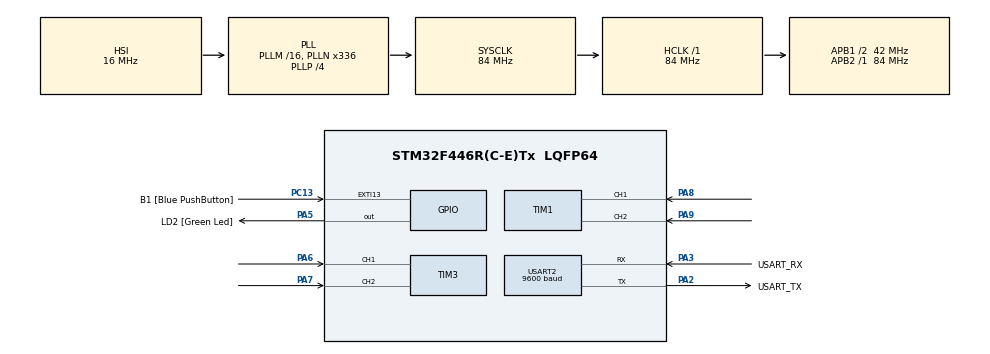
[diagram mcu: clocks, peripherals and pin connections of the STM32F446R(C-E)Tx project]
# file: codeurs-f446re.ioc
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Mcu.Family=STM32F4
PH0-OSC_IN.Signal=RCC_OSC_IN
RCC.CortexFreq_Value=84000000
PA14.GPIO_Label=TCK
TIM3.EncoderMode=TIM_ENCODERMODE_TI12
TIM1.EncoderMode=TIM_ENCODERMODE_TI12
PC13.GPIO_Label=B1 [Blue PushButton]
RCC.SYSCLKSource=RCC_SYSCLKSOURCE_PLLCLK
ProjectManager.StackSize=0x400
RCC.HCLKFreq_Value=84000000
RCC.APB2TimFreq_Value=84000000
RCC.AHBFreq_Value=84000000
PH0-OSC_IN.Mode=HSE-External-Oscillator
RCC.HSE_VALUE=8000000
PC14-OSC32_IN.Mode=LSE-External-Oscillator
PA14.Mode=Serial_Wire
PA8.Signal=S_TIM1_CH1
SH.S_TIM3_CH1.0=TIM3_CH1,Encoder_Interface
RCC.FLatency-AdvancedSettings=FLASH_LATENCY_2
PH1-OSC_OUT.Mode=HSE-External-Oscillator
Mcu.Package=LQFP64
PA6.Signal=S_TIM3_CH1
USART2.VirtualMode=VM_ASYNC
PA2.GPIO_Label=USART_TX
RCC.APB1TimFreq_Value=84000000
PA3.Signal=USART2_RX
PB3.GPIO_Label=SWO
PC15-OSC32_OUT.Mode=LSE-External-Oscillator
TIM3.CounterMode=TIM_COUNTERMODE_UP
TIM1.CounterMode=TIM_COUNTERMODE_UP
PC13.Signal=GPXTI13
RCC.APB1CLKDivider=RCC_HCLK_DIV2
PC14-OSC32_IN.Signal=RCC_OSC32_IN
USART2.BaudRate=9600
PA3.Mode=Asynchronous
PA13.Signal=SYS_JTMS-SWDIO
SH.S_TIM1_CH1.0=TIM1_CH1,Encoder_Interface
ProjectManager.TargetToolchain=STM32CubeIDE
TIM3.IC2Filter=10
PA9.Signal=S_TIM1_CH2
RCC.USBFreq_Value=168000000
PC15-OSC32_OUT.Signal=RCC_OSC32_OUT
PA5.Signal=GPIO_Output
SH.S_TIM3_CH2.0=TIM3_CH2,Encoder_Interface
TIM3.IC1Filter=10
board=NUCLEO-F446RE
RCC.VCOOutputFreq_Value=336000000
RCC.APB2Freq_Value=84000000
SH.S_TIM1_CH2.0=TIM1_CH2,Encoder_Interface
TIM1.IC2Filter=10
PH1-OSC_OUT.Signal=RCC_OSC_OUT
PA13.Mode=Serial_Wire
Mcu.Name=STM32F446R(C-E)Tx
PA13.GPIO_Label=TMS
PA2.Signal=USART2_TX
RCC.48MHZClocksFreq_Value=84000000
PB3.Signal=SYS_JTDO-SWO
RCC.SYSCLKFreq_VALUE=84000000
PA5.GPIO_Label=LD2 [Green Led]
TIM1.IC1Filter=10
PC13.GPIO_ModeDefaultEXTI=GPIO_MODE_IT_FALLING
PA14.Signal=SYS_JTCK-SWCLK
ProjectManager.HeapSize=0x200
RCC.HSI_VALUE=16000000
RCC.PLLP=RCC_PLLP_DIV4
NVIC.PriorityGroup=NVIC_PRIORITYGROUP_0
RCC.PLLN=336
PA2.Mode=Asynchronous
RCC.APB1Freq_Value=42000000
PA3.GPIO_Label=USART_RX
PA7.Signal=S_TIM3_CH2

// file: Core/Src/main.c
/* USER CODE BEGIN Header */
/**
  ******************************************************************************
  * @file           : main.c
  * @brief          : Main program body
  ******************************************************************************
  * @attention
  *
  * <h2><center>&copy; Copyright (c) 2021 STMicroelectronics.
  * All rights reserved.</center></h2>
  *
  * This software component is licensed by ST under BSD 3-Clause license,
  * the "License"; You may not use this file except in compliance with the
  * License. You may obtain a copy of the License at:
  *                        opensource.org/licenses/BSD-3-Clause
  *
  ******************************************************************************
  */
/* USER CODE END Header */
#include "main.h"
#include "tim.h"
#include "usart.h"
#include "gpio.h"

/* USER CODE BEGIN Includes */
#include <stdio.h>
#include "retarget.h"
/* USER CODE END Includes */

void SystemClock_Config(void);

int main(void)
{

  /* MCU Configuration--------------------------------------------------------*/

  /* Reset of all peripherals, Initializes the Flash interface and the Systick. */
  HAL_Init();

  /* Configure the system clock */
  SystemClock_Config();

  /* Initialize all configured peripherals */
  MX_GPIO_Init();
  MX_USART2_UART_Init();
  MX_TIM1_Init();
  MX_TIM3_Init();
  /* USER CODE BEGIN 2 */
  RetargetInit(&huart2);
  printf("codeurs-f446re");

  int i = 0, y = 0;
  HAL_TIM_Encoder_Start(&htim1, TIM_CHANNEL_ALL);
  HAL_TIM_Encoder_Start(&htim3, TIM_CHANNEL_ALL);
  /* USER CODE END 2 */

  /* Infinite loop */
  /* USER CODE BEGIN WHILE */
  while (1)
  {
	  i = TIM1->CNT;
	  y = TIM3->CNT;
	  //printf("Gauche = %d\r\n",i);
	  printf("Droite = %d\r\n",y);
    /* USER CODE END WHILE */

  }
}

void SystemClock_Config(void)
{
  RCC_OscInitTypeDef RCC_OscInitStruct = {0};
  RCC_ClkInitTypeDef RCC_ClkInitStruct = {0};

  /** Configure the main internal regulator output voltage
  */
  __HAL_RCC_PWR_CLK_ENABLE();
  __HAL_PWR_VOLTAGESCALING_CONFIG(PWR_REGULATOR_VOLTAGE_SCALE3);
  /** Initializes the RCC Oscillators according to the specified parameters
  * in the RCC_OscInitTypeDef structure.
  */
  RCC_OscInitStruct.OscillatorType = RCC_OSCILLATORTYPE_HSI;
  RCC_OscInitStruct.HSIState = RCC_HSI_ON;
  RCC_OscInitStruct.HSICalibrationValue = RCC_HSICALIBRATION_DEFAULT;
  RCC_OscInitStruct.PLL.PLLState = RCC_PLL_ON;
  RCC_OscInitStruct.PLL.PLLSource = RCC_PLLSOURCE_HSI;
  RCC_OscInitStruct.PLL.PLLM = 16;
  RCC_OscInitStruct.PLL.PLLN = 336;
  RCC_OscInitStruct.PLL.PLLP = RCC_PLLP_DIV4;
  RCC_OscInitStruct.PLL.PLLQ = 2;
  RCC_OscInitStruct.PLL.PLLR = 2;
  if (HAL_RCC_OscConfig(&RCC_OscInitStruct) != HAL_OK)
  {
    Error_Handler();
  }
  /** Initializes the CPU, AHB and APB buses clocks
  */
  RCC_ClkInitStruct.ClockType = RCC_CLOCKTYPE_HCLK|RCC_CLOCKTYPE_SYSCLK
                              |RCC_CLOCKTYPE_PCLK1|RCC_CLOCKTYPE_PCLK2;
  RCC_ClkInitStruct.SYSCLKSource = RCC_SYSCLKSOURCE_PLLCLK;
  RCC_ClkInitStruct.AHBCLKDivider = RCC_SYSCLK_DIV1;
  RCC_ClkInitStruct.APB1CLKDivider = RCC_HCLK_DIV2;
  RCC_ClkInitStruct.APB2CLKDivider = RCC_HCLK_DIV1;

  if (HAL_RCC_ClockConfig(&RCC_ClkInitStruct, FLASH_LATENCY_2) != HAL_OK)
  {
    Error_Handler();
  }
}

void Error_Handler(void)
{
  __disable_irq();
  while (1)
  {
  }
}

/************************ (C) COPYRIGHT STMicroelectronics *****END OF FILE****/
